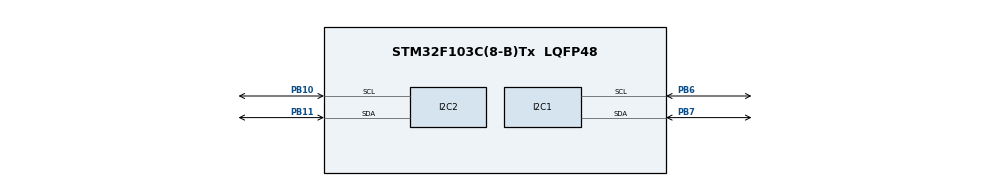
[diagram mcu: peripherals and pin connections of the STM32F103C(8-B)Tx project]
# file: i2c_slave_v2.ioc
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I2C2.OwnAddress=0x12
Mcu.Family=STM32F1
Mcu.Name=STM32F103C(8-B)Tx
Mcu.Package=LQFP48
NVIC.I2C1_ER_IRQn=true\:0\:0\:false\:false\:true\:true\:true\:true
NVIC.I2C1_EV_IRQn=true\:0\:0\:false\:false\:true\:true\:true\:true
NVIC.I2C2_ER_IRQn=true\:0\:0\:false\:false\:true\:true\:true\:true
NVIC.I2C2_EV_IRQn=true\:0\:0\:false\:false\:true\:true\:true\:true
NVIC.PriorityGroup=NVIC_PRIORITYGROUP_4
NVIC.TIM2_IRQn=true\:0\:0\:false\:false\:true\:true\:true\:true
PA13.Mode=Trace_Asynchronous_SW
PA13.Signal=SYS_JTMS-SWDIO
PA14.Mode=Trace_Asynchronous_SW
PA14.Signal=SYS_JTCK-SWCLK
PB10.Mode=I2C
PB10.Signal=I2C2_SCL
PB11.Mode=I2C
PB11.Signal=I2C2_SDA
PB3.Mode=Trace_Asynchronous_SW
PB3.Signal=SYS_JTDO-TRACESWO
PB6.Mode=I2C
PB6.Signal=I2C1_SCL
PB7.Mode=I2C
PB7.Signal=I2C1_SDA
ProjectManager.HeapSize=0x200
ProjectManager.StackSize=0x400
ProjectManager.TargetToolchain=STM32CubeIDE
RCC.APB1Freq_Value=8000000
RCC.APB2Freq_Value=8000000
VP_TIM2_VS_ClockSourceINT.Mode=Internal
board=custom

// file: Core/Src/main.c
/* USER CODE BEGIN Header */
/**
  ******************************************************************************
  * @file           : main.c
  * @brief          : Main program body
  ******************************************************************************
  * @attention
  *
  * Copyright (c) 2025 STMicroelectronics.
  * All rights reserved.
  *
  * This software is licensed under terms that can be found in the LICENSE file
  * in the root directory of this software component.
  * If no LICENSE file comes with this software, it is provided AS-IS.
  *
  ******************************************************************************
  */
/* USER CODE END Header */
#include "main.h"
#include "i2c.h"
#include "tim.h"
#include "gpio.h"

/* USER CODE BEGIN Includes */
#include <string.h>
#include <stdio.h>
#include "swo.h"
#include "i2c_slave.h"
#include "as5600.h"
/* USER CODE END Includes */

void SystemClock_Config(void);

int main(void)
{

  /* MCU Configuration--------------------------------------------------------*/

  /* Reset of all peripherals, Initializes the Flash interface and the Systick. */
  HAL_Init();

  /* Configure the system clock */
  SystemClock_Config();

  /* Initialize all configured peripherals */
  MX_GPIO_Init();
  MX_I2C2_Init();
  MX_I2C1_Init();
  MX_TIM2_Init();
  /* USER CODE BEGIN 2 */
  I2C_Slave_Init(&hi2c2);

  // Start timer interrupt for sensor reading (100Hz - every 10ms)
  HAL_TIM_Base_Start_IT(&htim2);

  log_error("Print error testing\n");
  /* USER CODE END 2 */

  /* Infinite loop */
  while (1)
  {

  }
}

void SystemClock_Config(void)
{
  RCC_OscInitTypeDef RCC_OscInitStruct = {0};
  RCC_ClkInitTypeDef RCC_ClkInitStruct = {0};

  /** Initializes the RCC Oscillators according to the specified parameters
  * in the RCC_OscInitTypeDef structure.
  */
  RCC_OscInitStruct.OscillatorType = RCC_OSCILLATORTYPE_HSI;
  RCC_OscInitStruct.HSIState = RCC_HSI_ON;
  RCC_OscInitStruct.HSICalibrationValue = RCC_HSICALIBRATION_DEFAULT;
  RCC_OscInitStruct.PLL.PLLState = RCC_PLL_NONE;
  if (HAL_RCC_OscConfig(&RCC_OscInitStruct) != HAL_OK)
  {
    Error_Handler();
  }

  /** Initializes the CPU, AHB and APB buses clocks
  */
  RCC_ClkInitStruct.ClockType = RCC_CLOCKTYPE_HCLK|RCC_CLOCKTYPE_SYSCLK
                              |RCC_CLOCKTYPE_PCLK1|RCC_CLOCKTYPE_PCLK2;
  RCC_ClkInitStruct.SYSCLKSource = RCC_SYSCLKSOURCE_HSI;
  RCC_ClkInitStruct.AHBCLKDivider = RCC_SYSCLK_DIV1;
  RCC_ClkInitStruct.APB1CLKDivider = RCC_HCLK_DIV1;
  RCC_ClkInitStruct.APB2CLKDivider = RCC_HCLK_DIV1;

  if (HAL_RCC_ClockConfig(&RCC_ClkInitStruct, FLASH_LATENCY_0) != HAL_OK)
  {
    Error_Handler();
  }
}

/* USER CODE BEGIN 4 */

// Timer interrupt callback - called every 10ms (100Hz)
void HAL_TIM_PeriodElapsedCallback(TIM_HandleTypeDef *htim)
{
    if (htim->Instance == TIM2)
    {
        // Read sensor data in interrupt
        as5600_retrieve_angle();
        as5600_retrieve_status();
    }
}
/* USER CODE END 4 */

void Error_Handler(void)
{
  __disable_irq();
  while (1)
  {
  }
}
